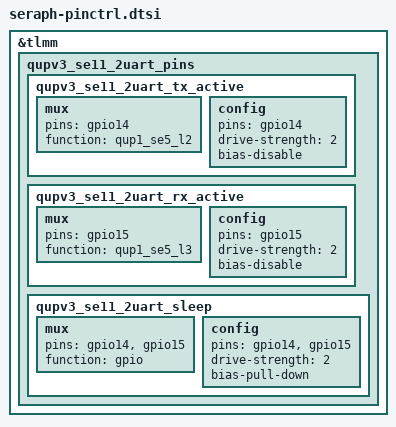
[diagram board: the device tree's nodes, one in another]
&tlmm {
	qupv3_se11_2uart_pins: qupv3_se11_2uart_pins {
		qupv3_se11_2uart_tx_active: qupv3_se11_2uart_tx_active {
			mux {
				pins = "gpio14";
				function = "qup1_se5_l2";
			};

			config {
				pins = "gpio14";
				drive-strength = <2>;
				bias-disable;
			};
		};

		qupv3_se11_2uart_rx_active: qupv3_se11_2uart_rx_active {
			mux {
				pins = "gpio15";
				function = "qup1_se5_l3";
			};

			config {
				pins = "gpio15";
				drive-strength = <2>;
				bias-disable;
			};
		};

		qupv3_se11_2uart_sleep: qupv3_se11_2uart_sleep {
			mux {
				pins = "gpio14", "gpio15";
				function = "gpio";
			};

			config {
				pins = "gpio14", "gpio15";
				drive-strength = <2>;
				bias-pull-down;
			};
		};
	};
};
